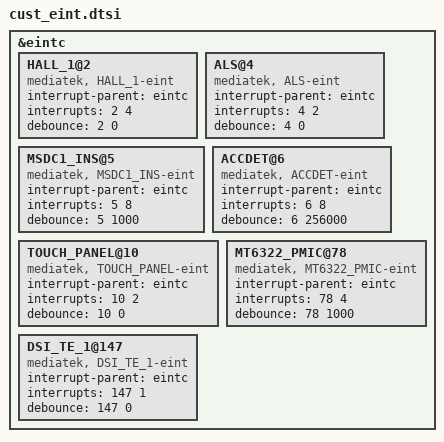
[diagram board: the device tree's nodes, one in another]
/*
 * Generated by MTK SP Drv_CodeGen Version 03.13.6  for MT6753. Copyright MediaTek Inc. (C) 2013.
 * Tue Mar 28 19:28:23 2017
 * Do Not Modify the File.
 */

/*************************
 * EINT DTSI File
*************************/

&eintc {
	HALL_1@2 {
		compatible = "mediatek, HALL_1-eint";
		interrupt-parent = <&eintc>;
		interrupts = <2 4>;
		debounce = <2 0>;
	};

	ALS@4 {
		compatible = "mediatek, ALS-eint";
		interrupt-parent = <&eintc>;
		interrupts = <4 2>;
		debounce = <4 0>;
	};

	MSDC1_INS@5 {
		compatible = "mediatek, MSDC1_INS-eint";
		interrupt-parent = <&eintc>;
		interrupts = <5 8>;
		debounce = <5 1000>;
	};

	ACCDET@6 {
		compatible = "mediatek, ACCDET-eint";
		interrupt-parent = <&eintc>;
		interrupts = <6 8>;
		debounce = <6 256000>;
	};

	TOUCH_PANEL@10 {
		compatible = "mediatek, TOUCH_PANEL-eint";
		interrupt-parent = <&eintc>;
		interrupts = <10 2>;
		debounce = <10 0>;
	};

	MT6322_PMIC@78 {
		compatible = "mediatek, MT6322_PMIC-eint";
		interrupt-parent = <&eintc>;
		interrupts = <78 4>;
		debounce = <78 1000>;
	};

	DSI_TE_1@147 {
		compatible = "mediatek, DSI_TE_1-eint";
		interrupt-parent = <&eintc>;
		interrupts = <147 1>;
		debounce = <147 0>;
	};

};
